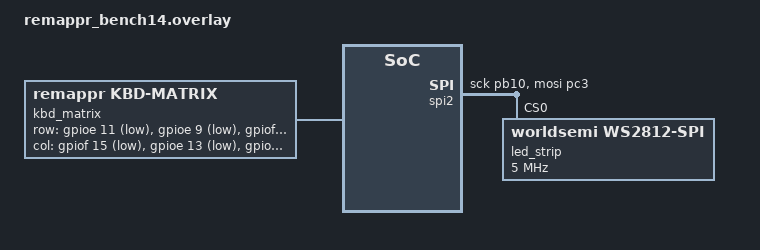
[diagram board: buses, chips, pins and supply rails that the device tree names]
/*
 * Remappr Bench 14 — Remappr shield (generated by remappr).
 *
 * Drop this directory into a remappr-firmware checkout under
 * boards/shields/remappr_bench14/ and build with -DSHIELD=remappr_bench14. Verify the
 * row/col GPIO specs against your wiring — remappr derives the matrix
 * cells from physical key position, not the electrical matrix.
 *
 * SPDX-License-Identifier: Apache-2.0
 */

#include <zephyr/dt-bindings/input/input-event-codes.h>
#include <zephyr/dt-bindings/input/keymap.h>
#include <dt-bindings/remappr/keys.h>
#include <dt-bindings/remappr/layout.h>
#include <remappr/keymap-tokens.dtsi>
#include <remappr/behavior-tokens.dtsi>
#include <zephyr/dt-bindings/led/led.h>
#include <zephyr/dt-bindings/dma/stm32_dma.h>

/ {
	kbd_matrix: kbd-matrix {
		compatible = "remappr,kbd-matrix";
		diode-direction = "row2col";
		poll-period-ms = <2>;
		row-gpios =
			<&gpioe 11 GPIO_ACTIVE_LOW>,
			<&gpioe 9 GPIO_ACTIVE_LOW>,
			<&gpiof 13 GPIO_ACTIVE_LOW>,
			<&gpioa 3 GPIO_ACTIVE_LOW>;
		col-gpios =
			<&gpiof 15 (GPIO_PULL_UP | GPIO_ACTIVE_LOW)>,
			<&gpioe 13 (GPIO_PULL_UP | GPIO_ACTIVE_LOW)>,
			<&gpiof 14 (GPIO_PULL_UP | GPIO_ACTIVE_LOW)>,
			<&gpioa 2 (GPIO_PULL_UP | GPIO_ACTIVE_LOW)>;

		keymap {
			compatible = "input-keymap";
			keymap = <
				MATRIX_KEY(0, 0, REMAPPR_KB_POS_BASE + 0) MATRIX_KEY(0, 1, REMAPPR_KB_POS_BASE + 1) MATRIX_KEY(0, 2, REMAPPR_KB_POS_BASE + 2)
				MATRIX_KEY(1, 0, REMAPPR_KB_POS_BASE + 3) MATRIX_KEY(1, 1, REMAPPR_KB_POS_BASE + 4) MATRIX_KEY(1, 2, REMAPPR_KB_POS_BASE + 5)
				MATRIX_KEY(2, 0, REMAPPR_KB_POS_BASE + 6) MATRIX_KEY(2, 1, REMAPPR_KB_POS_BASE + 7) MATRIX_KEY(2, 2, REMAPPR_KB_POS_BASE + 8) MATRIX_KEY(2, 3, REMAPPR_KB_POS_BASE + 9)
				MATRIX_KEY(3, 0, REMAPPR_KB_POS_BASE + 10) MATRIX_KEY(3, 1, REMAPPR_KB_POS_BASE + 11) MATRIX_KEY(3, 2, REMAPPR_KB_POS_BASE + 12) MATRIX_KEY(3, 3, REMAPPR_KB_POS_BASE + 13)
			>;
			row-size = <4>;
			col-size = <4>;
		};
	};

	remappr_keymap: remappr-keymap {
		compatible = "remappr,keymap";
		scan = <&kbd_matrix>;
		columns = <4>;
		rows = <3 3 4 4>;
		max-layers = <4>;
		placement = <
				KEY(&x 0 &y 0) KEY(&x 1 &y 0) KEY(&x 2 &y 0)
				KEY(&x 0 &y 1) KEY(&x 1 &y 1) KEY(&x 2 &y 1)
				KEY(&x 0 &y 2) KEY(&x 1 &y 2) KEY(&x 2 &y 2) KEY(&x 3 &y 2)
				KEY(&x 0 &y 3) KEY(&x 1 &y 3) KEY(&x 2 &y 3) KEY(&x 3 &y 3)
		>;
		layer_0 {
			compatible = "remappr,keymap-layer";
			index = <0>;
			actions = <
				&key 0x1E &key 0x1F &key 0x20
				&key 0x14 &key 0x1A &key 0x08
				&key 0x04 &key 0x16 &key 0x07 &key 0x09
				&key 0x1D &key 0x1B &key 0x06 &key 0x19
			>;
		};
	};
};

&spi2 {
	pinctrl-0 = <&spi2_sck_pb10 &spi2_mosi_pc3>;
	pinctrl-names = "default";
	status = "okay";

	/* GPDMA streams the strip buffer gaplessly — needed on STM32 for
	   color-correct output (a CPU/FIFO transfer inserts inter-byte gaps
	   a latch-sensitive WS2812 reads as a reset). Both channels required. */
	dmas = <&gpdma1 0 9 (STM32_DMA_PERIPH_TX | STM32_DMA_PRIORITY_HIGH)>, <&gpdma1 1 8 (STM32_DMA_PERIPH_RX | STM32_DMA_PRIORITY_HIGH)>;
	dma-names = "tx", "rx";

	led_strip: ws2812@0 {
		compatible = "worldsemi,ws2812-spi";
		reg = <0>;
		spi-max-frequency = <5000000>;
		chain-length = <14>;
		/* One low lead-in bit, then the pulse: 5000000 Hz SPI clock. */
		spi-one-frame = <0x78>;
		spi-zero-frame = <0x60>;
		color-mapping = <LED_COLOR_ID_GREEN LED_COLOR_ID_RED LED_COLOR_ID_BLUE>;
	};
};

/ {
	chosen {
		/* Runtime RGB service renders the per-key map / effects here. */
		remappr,led-strip = &led_strip;
	};
};
